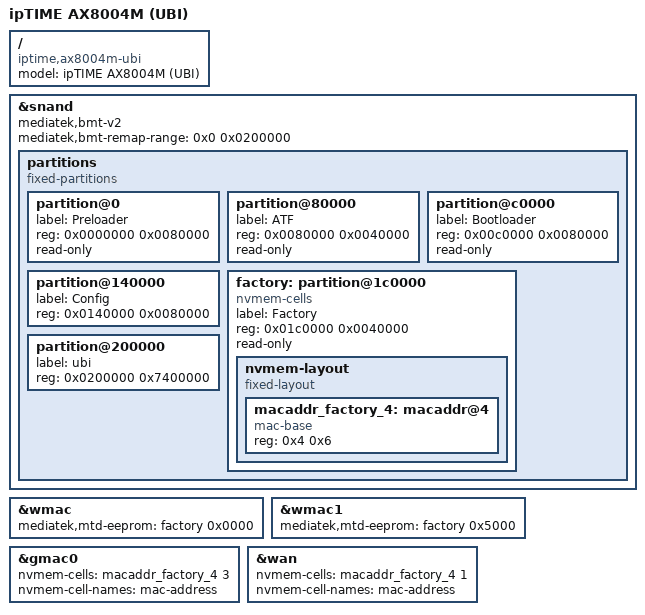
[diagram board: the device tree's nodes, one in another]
// SPDX-License-Identifier: (GPL-2.0-only OR MIT)

/dts-v1/;
#include "mt7622-iptime-ax8004m.dtsi"

/ {
	model = "ipTIME AX8004M (UBI)";
	compatible = "iptime,ax8004m-ubi", "mediatek,mt7622";
};

&snand {
	mediatek,bmt-v2;
	mediatek,bmt-remap-range = <0x0 0x0200000>;

	partitions {
		compatible = "fixed-partitions";
		#address-cells = <1>;
		#size-cells = <1>;

		partition@0 {
			label = "Preloader";
			reg = <0x0000000 0x0080000>;
			read-only;
		};

		partition@80000 {
			label = "ATF";
			reg = <0x0080000 0x0040000>;
			read-only;
		};

		partition@c0000 {
			label = "Bootloader";
			reg = <0x00c0000 0x0080000>;
			read-only;
		};

		partition@140000 {
			label = "Config";
			reg = <0x0140000 0x0080000>;
		};

		factory: partition@1c0000 {
			label = "Factory";
			reg = <0x01c0000 0x0040000>;
			read-only;
		};

		partition@200000 {
			label = "ubi";
			reg = <0x0200000 0x7400000>;
		};
	};
};

&factory {
	compatible = "nvmem-cells";
	#address-cells = <1>;
	#size-cells = <1>;

	nvmem-layout {
		compatible = "fixed-layout";
		#address-cells = <1>;
		#size-cells = <1>;

		macaddr_factory_4: macaddr@4 {
			compatible = "mac-base";
			reg = <0x4 0x6>;
			#nvmem-cell-cells = <1>;
		};
	};
};

&wmac {
	mediatek,mtd-eeprom = <&factory 0x0000>;
	status = "okay";
};

&wmac1 {
	mediatek,mtd-eeprom = <&factory 0x5000>;
};

&gmac0 {
	nvmem-cells = <&macaddr_factory_4 3>;
	nvmem-cell-names = "mac-address";
};

&wan {
	nvmem-cells = <&macaddr_factory_4 1>;
	nvmem-cell-names = "mac-address";
};
